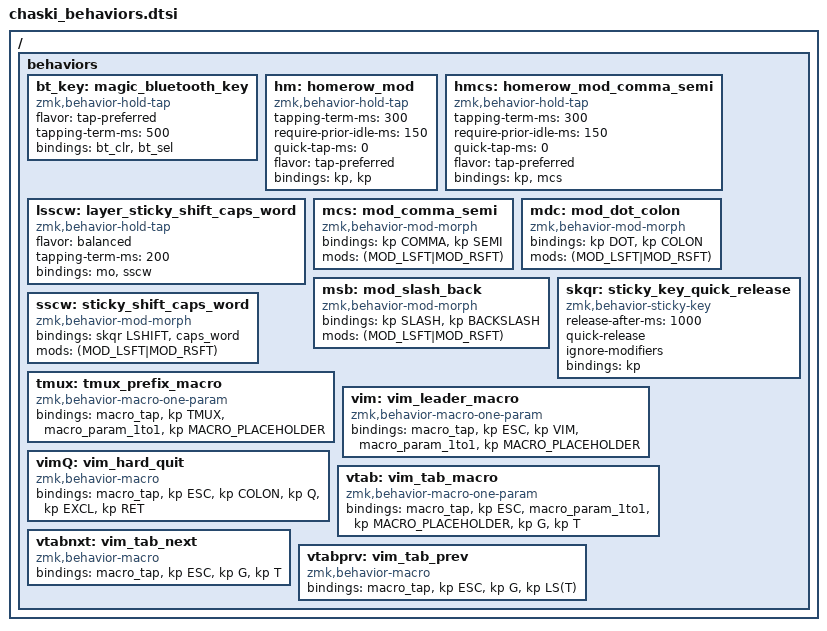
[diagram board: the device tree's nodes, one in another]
// In case you want to change your leader keys
#define TMUX RC(B)
#define VIM SPACE

/ {
    behaviors {
        bt_key: magic_bluetooth_key {
            compatible = "zmk,behavior-hold-tap";
            #binding-cells = <2>;
            flavor = "tap-preferred";
            tapping-term-ms = <500>;
            bindings = <&bt_clr>, <&bt_sel>;
        };

        hm: homerow_mod {
            compatible = "zmk,behavior-hold-tap";
            #binding-cells = <2>;
            tapping-term-ms = <300>;
            require-prior-idle-ms = <150>;
            quick-tap-ms = <0>;
            flavor = "tap-preferred";
            bindings = <&kp>, <&kp>;
        };

        hmcs: homerow_mod_comma_semi {
            compatible = "zmk,behavior-hold-tap";
            #binding-cells = <2>;
            tapping-term-ms = <300>;
            require-prior-idle-ms = <150>;
            quick-tap-ms = <0>;
            flavor = "tap-preferred";
            bindings = <&kp>, <&mcs>;
        };

        lsscw: layer_sticky_shift_caps_word {
            compatible = "zmk,behavior-hold-tap";
            #binding-cells = <2>;
            flavor = "balanced";
            tapping-term-ms = <200>;
            bindings = <&mo>, <&sscw>;
        };

        mcs: mod_comma_semi {
            compatible = "zmk,behavior-mod-morph";
            #binding-cells = <0>;
            bindings = <&kp COMMA>, <&kp SEMI>;
            mods = <(MOD_LSFT|MOD_RSFT)>;
        };

        mdc: mod_dot_colon {
            compatible = "zmk,behavior-mod-morph";
            #binding-cells = <0>;
            bindings = <&kp DOT>, <&kp COLON>;
            mods = <(MOD_LSFT|MOD_RSFT)>;
        };

        msb: mod_slash_back {
            compatible = "zmk,behavior-mod-morph";
            #binding-cells = <0>;
            bindings = <&kp SLASH>, <&kp BACKSLASH>;
            mods = <(MOD_LSFT|MOD_RSFT)>;
        };

        skqr: sticky_key_quick_release {
            compatible = "zmk,behavior-sticky-key";
            #binding-cells = <1>;
            release-after-ms = <1000>;
            quick-release;
            ignore-modifiers;
            bindings = <&kp>;
        };

        sscw: sticky_shift_caps_word {
            compatible = "zmk,behavior-mod-morph";
            #binding-cells = <0>;
            bindings = <&skqr LSHIFT>, <&caps_word>;
            mods = <(MOD_LSFT|MOD_RSFT)>;
        };

        tmux: tmux_prefix_macro {
            compatible = "zmk,behavior-macro-one-param";
            #binding-cells = <1>;
            bindings =
                <&macro_tap &kp TMUX>,
                <&macro_param_1to1 &kp MACRO_PLACEHOLDER>;
        };

        vim: vim_leader_macro {
            compatible = "zmk,behavior-macro-one-param";
            #binding-cells = <1>;
            bindings =
                <&macro_tap &kp ESC &kp VIM>,
                <&macro_param_1to1 &kp MACRO_PLACEHOLDER>;
        };

        vimQ: vim_hard_quit {
            compatible = "zmk,behavior-macro";
            #binding-cells = <0>;
            bindings = <&macro_tap &kp ESC>, <&kp COLON &kp Q &kp EXCL &kp RET>;
        };

        vtab: vim_tab_macro {
            compatible = "zmk,behavior-macro-one-param";
            #binding-cells = <1>;
            bindings =
                <&macro_tap &kp ESC>,
                <&macro_param_1to1 &kp MACRO_PLACEHOLDER>,
                <&kp G &kp T>;
        };

        vtabnxt: vim_tab_next {
            compatible = "zmk,behavior-macro";
            #binding-cells = <0>;
            bindings = <&macro_tap &kp ESC>, <&kp G &kp T>;
        };

        vtabprv: vim_tab_prev {
            compatible = "zmk,behavior-macro";
            #binding-cells = <0>;
            bindings = <&macro_tap &kp ESC>, <&kp G &kp LS(T)>;
        };
    };
};

// vim: expandtab softtabstop=4 shiftwidth=4
